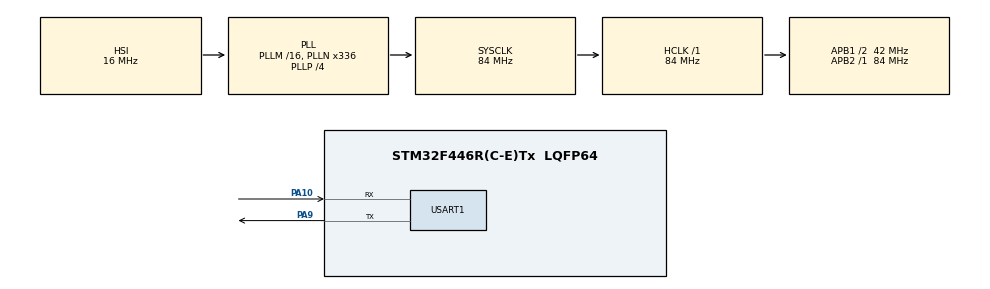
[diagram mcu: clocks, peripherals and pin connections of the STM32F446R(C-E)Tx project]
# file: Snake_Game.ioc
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FREERTOS.MEMORY_ALLOCATION=1
FREERTOS.Tasks01=defaultTask,0,128,StartDefaultTask,Default,NULL,Static,defaultTaskBuffer,defaultTaskControlBlock
Mcu.Family=STM32F4
Mcu.Name=STM32F446R(C-E)Tx
Mcu.Package=LQFP64
NVIC.PriorityGroup=NVIC_PRIORITYGROUP_4
NVIC.USART1_IRQn=true\:5\:0\:false\:false\:true\:true\:true\:true\:true
PA10.Mode=Asynchronous
PA10.Signal=USART1_RX
PA9.Mode=Asynchronous
PA9.Signal=USART1_TX
ProjectManager.HeapSize=0x200
ProjectManager.StackSize=0x400
ProjectManager.TargetToolchain=STM32CubeIDE
RCC.AHBFreq_Value=84000000
RCC.APB1CLKDivider=RCC_HCLK_DIV2
RCC.APB1Freq_Value=42000000
RCC.APB1TimFreq_Value=84000000
RCC.APB2Freq_Value=84000000
RCC.APB2TimFreq_Value=84000000
RCC.CortexFreq_Value=84000000
RCC.FLatency-AdvancedSettings=FLASH_LATENCY_2
RCC.HCLKFreq_Value=84000000
RCC.HSE_VALUE=8000000
RCC.HSI_VALUE=16000000
RCC.LSE_VALUE=32768
RCC.PLLN=336
RCC.PLLP=RCC_PLLP_DIV4
RCC.SYSCLKFreq_VALUE=84000000
RCC.SYSCLKSource=RCC_SYSCLKSOURCE_PLLCLK
RCC.USBFreq_Value=168000000
RCC.VCOOutputFreq_Value=336000000
USART1.VirtualMode=VM_ASYNC
VP_FREERTOS_VS_CMSIS_V1.Mode=CMSIS_V1
board=NUCLEO-F446RE

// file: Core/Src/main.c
/* USER CODE BEGIN Header */
/**
 ******************************************************************************
 * @file           : main.c
 * @brief          : Main program body
 ******************************************************************************
 * @attention
 *
 * Copyright (c) 2023 STMicroelectronics.
 * All rights reserved.
 *
 * This software is licensed under terms that can be found in the LICENSE file
 * in the root directory of this software component.
 * If no LICENSE file comes with this software, it is provided AS-IS.
 *
 ******************************************************************************
 */
/* USER CODE END Header */
#include "main.h"

/* USER CODE BEGIN Includes */
#include "Game.h"
#include "ScreenFrame.h"
/* USER CODE END Includes */

UART_HandleTypeDef huart1;

/* USER CODE BEGIN PV */

/* GAME AO*/
static StackType_t game_stack[200]; // thread stack
static Event *game_queue[10]; // event queue
static Game game; // The Game object
Active *AO_Game = &game.super; // The Game active object

/* SCREENFRAME AO */
static StackType_t screen_frame_stack[200]; // thread stack
static Event *screen_frame_queue[10]; // event queue
static ScreenFrame screen_frame; // The Screen Frame object
Active *AO_ScreenFrame = &screen_frame.super; // The Screen Frame active object

/* USER CODE END PV */

static void SystemClock_Config(void);
static void MX_GPIO_Init(void);
static void MX_USART1_UART_Init(void);

/* USER CODE BEGIN 0 */

/* Executed when the UART completes a receive */
void HAL_UART_RxCpltCallback(UART_HandleTypeDef *huart) {
	if (huart->Instance == USART1) {
		static const Event e = { USER_IN_SIG };
		BaseType_t xHigherPriorityTaskWoken;
		Active_postFromISR(AO_Game, &e, &xHigherPriorityTaskWoken); // send a USER_IN_SIG to the Game AO
	}
}

/* Enable the Tick Hook in FreeRTOSConfig to use time events*/
void vApplicationTickHook(void) {
	BaseType_t xHigherPriorityTaskWoken;
	TimeEvent_tickFromISR(&xHigherPriorityTaskWoken);
}

/* USER CODE END 0 */

int main(void) {

	/* MCU Configuration--------------------------------------------------------*/

	/* Reset of all peripherals, Initializes the Flash interface and the Systick. */
	HAL_Init();

	/* Configure the system clock */
	SystemClock_Config();

	/* Initialize all configured peripherals */
	MX_GPIO_Init();
	MX_USART1_UART_Init();
	/* USER CODE BEGIN 2 */
	Game_ctor(&game, &huart1); /* construct the Game */
	ScreenFrame_ctor(&screen_frame, &huart1); /* construct the ScreenFrame */

	/* Start the threads */
	Active_start(AO_Game, 1, game_queue,
			sizeof(game_queue) / sizeof(game_queue[0]), game_stack,
			sizeof(game_stack) / sizeof(game_stack[0]));
	Active_start(AO_ScreenFrame, 2, screen_frame_queue,
			sizeof(screen_frame_queue) / sizeof(game_queue[0]),
			screen_frame_stack,
			sizeof(screen_frame_stack) / sizeof(screen_frame_stack[0]));
	/* USER CODE END 2 */

	/* Start scheduler */
	vTaskStartScheduler();
	/* We should never get here as control is now taken by the scheduler */
	/* Infinite loop */
	while (1) {

	}
}

void SystemClock_Config(void) {
	RCC_OscInitTypeDef RCC_OscInitStruct = { 0 };
	RCC_ClkInitTypeDef RCC_ClkInitStruct = { 0 };

	/** Configure the main internal regulator output voltage
	 */
	__HAL_RCC_PWR_CLK_ENABLE();
	__HAL_PWR_VOLTAGESCALING_CONFIG(PWR_REGULATOR_VOLTAGE_SCALE3);

	/** Initializes the RCC Oscillators according to the specified parameters
	 * in the RCC_OscInitTypeDef structure.
	 */
	RCC_OscInitStruct.OscillatorType = RCC_OSCILLATORTYPE_HSI;
	RCC_OscInitStruct.HSIState = RCC_HSI_ON;
	RCC_OscInitStruct.HSICalibrationValue = RCC_HSICALIBRATION_DEFAULT;
	RCC_OscInitStruct.PLL.PLLState = RCC_PLL_ON;
	RCC_OscInitStruct.PLL.PLLSource = RCC_PLLSOURCE_HSI;
	RCC_OscInitStruct.PLL.PLLM = 16;
	RCC_OscInitStruct.PLL.PLLN = 336;
	RCC_OscInitStruct.PLL.PLLP = RCC_PLLP_DIV4;
	RCC_OscInitStruct.PLL.PLLQ = 2;
	RCC_OscInitStruct.PLL.PLLR = 2;
	if (HAL_RCC_OscConfig(&RCC_OscInitStruct) != HAL_OK) {
		Error_Handler();
	}

	/** Initializes the CPU, AHB and APB buses clocks
	 */
	RCC_ClkInitStruct.ClockType = RCC_CLOCKTYPE_HCLK | RCC_CLOCKTYPE_SYSCLK
			| RCC_CLOCKTYPE_PCLK1 | RCC_CLOCKTYPE_PCLK2;
	RCC_ClkInitStruct.SYSCLKSource = RCC_SYSCLKSOURCE_PLLCLK;
	RCC_ClkInitStruct.AHBCLKDivider = RCC_SYSCLK_DIV1;
	RCC_ClkInitStruct.APB1CLKDivider = RCC_HCLK_DIV2;
	RCC_ClkInitStruct.APB2CLKDivider = RCC_HCLK_DIV1;

	if (HAL_RCC_ClockConfig(&RCC_ClkInitStruct, FLASH_LATENCY_2) != HAL_OK) {
		Error_Handler();
	}
}

static void MX_USART1_UART_Init(void) {

	huart1.Instance = USART1;
	huart1.Init.BaudRate = 115200;
	huart1.Init.WordLength = UART_WORDLENGTH_8B;
	huart1.Init.StopBits = UART_STOPBITS_1;
	huart1.Init.Parity = UART_PARITY_NONE;
	huart1.Init.Mode = UART_MODE_TX_RX;
	huart1.Init.HwFlowCtl = UART_HWCONTROL_NONE;
	huart1.Init.OverSampling = UART_OVERSAMPLING_16;
	if (HAL_UART_Init(&huart1) != HAL_OK) {
		Error_Handler();
	}

}

static void MX_GPIO_Init(void) {

	/* GPIO Ports Clock Enable */
	__HAL_RCC_GPIOA_CLK_ENABLE();

}

void Error_Handler(void) {
	__disable_irq();
	while (1) {
	}
}
